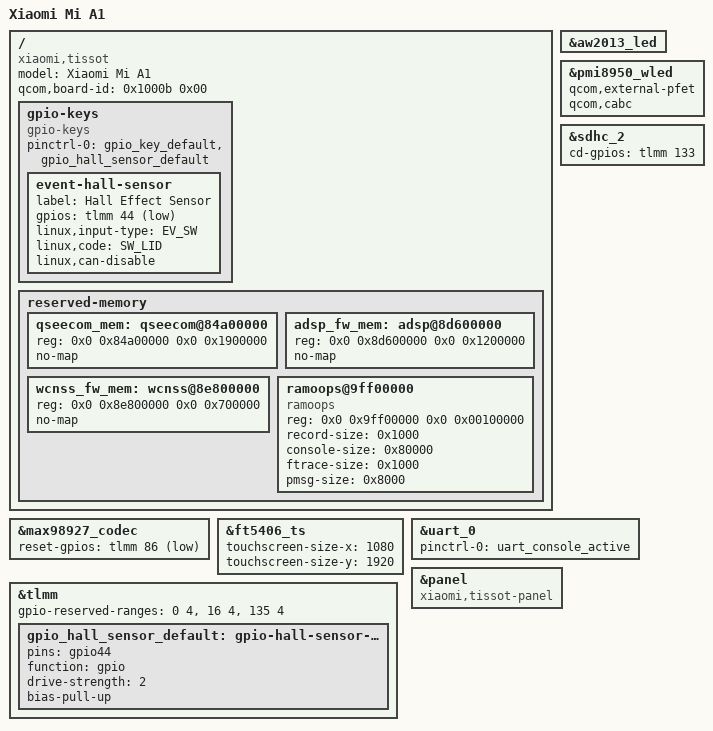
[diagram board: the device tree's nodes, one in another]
// SPDX-License-Identifier: BSD-3-Clause
/*
 * Copyright (c) 2022, Danila Tikhonov <JIaxyga@protonmail.com>
 * Copyright (c) 2022, Anton Bambura <jenneron@protonmail.com>
 */
/dts-v1/;

#include "msm8953-xiaomi-common.dtsi"

/delete-node/ &adsp_fw_mem;
/delete-node/ &qseecom_mem;
/delete-node/ &wcnss_fw_mem;

/ {
	model = "Xiaomi Mi A1";
	compatible = "xiaomi,tissot", "qcom,msm8953";
	qcom,board-id = <0x1000b 0x00>;

	gpio-keys {
		compatible = "gpio-keys";

		pinctrl-names = "default";
		pinctrl-0 = <&gpio_key_default>, <&gpio_hall_sensor_default>;

		event-hall-sensor {
			label = "Hall Effect Sensor";
			gpios = <&tlmm 44 GPIO_ACTIVE_LOW>;
			linux,input-type = <EV_SW>;
			linux,code = <SW_LID>;
			linux,can-disable;
		};
	};

	reserved-memory {
		qseecom_mem: qseecom@84a00000 {
			reg = <0x0 0x84a00000 0x0 0x1900000>;
			no-map;
		};

		adsp_fw_mem: adsp@8d600000 {
			reg = <0x0 0x8d600000 0x0 0x1200000>;
			no-map;
		};

		wcnss_fw_mem: wcnss@8e800000 {
			reg = <0x0 0x8e800000 0x0 0x700000>;
			no-map;
		};

		ramoops@9ff00000 {
			compatible = "ramoops";
			reg = <0x0 0x9ff00000 0x0 0x00100000>;
			record-size = <0x1000>;
			console-size = <0x80000>;
			ftrace-size = <0x1000>;
			pmsg-size = <0x8000>;
		};
	};
};

&max98927_codec {
	status = "okay";

	reset-gpios = <&tlmm 86 GPIO_ACTIVE_LOW>;
};

&aw2013_led {
	status = "okay";
};

&ft5406_ts {
	status = "okay";

	touchscreen-size-x = <1080>;
	touchscreen-size-y = <1920>;
};

&pmi8950_wled {
	qcom,external-pfet;
	qcom,cabc;
};

&sdhc_2 {
	cd-gpios = <&tlmm 133 GPIO_ACTIVE_HIGH>;
};

&tlmm {
	gpio-reserved-ranges = <0 4>, <16 4>, <135 4>;

	gpio_hall_sensor_default: gpio-hall-sensor-state {
		pins = "gpio44";
		function = "gpio";
		drive-strength = <2>;
		bias-pull-up;
	};
};

&uart_0 {
	pinctrl-names = "default";
	pinctrl-0 = <&uart_console_active>;

	status = "okay";
};

&panel {
	compatible = "xiaomi,tissot-panel";
};
